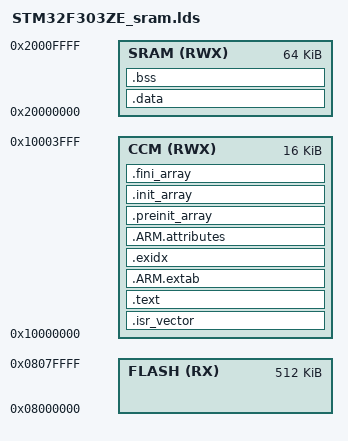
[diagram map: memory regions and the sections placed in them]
/* Generated by LinkerScriptGenerator [http://visualgdb.com/tools/LinkerScriptGenerator]
 * Target: STM32F303ZE
 * The file is provided under the BSD license.
 */

ENTRY(Reset_Handler)

MEMORY
{
	FLASH (RX) : ORIGIN = 0x08000000, LENGTH = 512K
	CCM (RWX)  : ORIGIN = 0x10000000, LENGTH = 16K
	SRAM (RWX) : ORIGIN = 0x20000000, LENGTH = 64K
}

_estack = 0x10004000;

SECTIONS
{
	.isr_vector :
	{
		. = ALIGN(4);
		KEEP(*(.isr_vector))
		. = ALIGN(4);
	} > CCM

	.text :
	{
		. = ALIGN(4);
		_stext = .;

		*(.text)
		*(.text*)
		*(.rodata)
		*(.rodata*)
		*(.glue_7)
		*(.glue_7t)
		KEEP(*(.init))
		KEEP(*(.fini))
		. = ALIGN(4);
		_etext = .;

	} > CCM

	.ARM.extab :
	{
		. = ALIGN(4);
		*(.ARM.extab)
		*(.gnu.linkonce.armextab.*)
		. = ALIGN(4);
	} > CCM

	.exidx :
	{
		. = ALIGN(4);
		PROVIDE(__exidx_start = .);
		*(.ARM.exidx*)
		. = ALIGN(4);
		PROVIDE(__exidx_end = .);
	} > CCM

	.ARM.attributes :
	{
		*(.ARM.attributes)
	} > CCM

	.preinit_array :
	{
		PROVIDE(__preinit_array_start = .);
		KEEP(*(.preinit_array*))
		PROVIDE(__preinit_array_end = .);
	} > CCM

	.init_array :
	{
		PROVIDE(__init_array_start = .);
		KEEP(*(SORT(.init_array.*)))
		KEEP(*(.init_array*))
		PROVIDE(__init_array_end = .);
	} > CCM

	.fini_array :
	{
		PROVIDE(__fini_array_start = .);
		KEEP(*(.fini_array*))
		KEEP(*(SORT(.fini_array.*)))
		PROVIDE(__fini_array_end = .);
	} > CCM

	.data :
	{
		. = ALIGN(4);
		_sidata = .;

		_sdata = _sidata;

		PROVIDE(__data_start__ = _sdata);
		*(.data)
		*(.data*)
		. = ALIGN(4);
		_edata = .;

		PROVIDE(__data_end__ = _edata);
	} > SRAM

	.bss :
	{
		. = ALIGN(4);
		_sbss = .;

		PROVIDE(__bss_start__ = _sbss);
		*(.bss)
		*(.bss*)
		*(COMMON)
		. = ALIGN(4);
		_ebss = .;

		PROVIDE(__bss_end__ = _ebss);
	} > SRAM

	PROVIDE(end = .);

}

